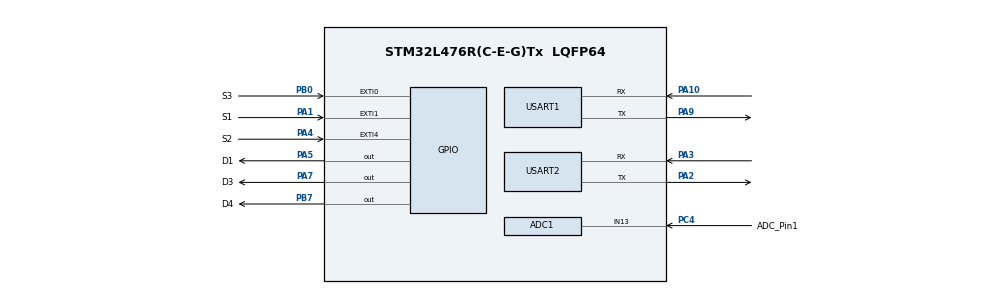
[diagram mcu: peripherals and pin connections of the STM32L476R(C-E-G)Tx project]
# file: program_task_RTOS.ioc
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ADC1.Channel-1\#ChannelRegularConversion=ADC_CHANNEL_13
ADC1.NbrOfConversionFlag=1
ADC1.OffsetNumber-1\#ChannelRegularConversion=ADC_OFFSET_NONE
ADC1.Rank-1\#ChannelRegularConversion=1
ADC1.SamplingTime-1\#ChannelRegularConversion=ADC_SAMPLETIME_2CYCLES_5
ADC1.master=1
FREERTOS.Tasks01=defaultTask,0,128,StartDefaultTask,Default,NULL,Dynamic,NULL,NULL
Mcu.Family=STM32L4
Mcu.Name=STM32L476R(C-E-G)Tx
Mcu.Package=LQFP64
NVIC.EXTI0_IRQn=true\:5\:0\:false\:false\:true\:true\:true\:true\:true
NVIC.EXTI1_IRQn=true\:5\:0\:false\:false\:true\:true\:true\:true\:true
NVIC.EXTI4_IRQn=true\:5\:0\:false\:false\:true\:true\:true\:true\:true
NVIC.PriorityGroup=NVIC_PRIORITYGROUP_4
PA1.GPIO_Label=S1
PA1.Signal=GPXTI1
PA10.Mode=Asynchronous
PA10.Signal=USART1_RX
PA2.Mode=Asynchronous
PA2.Signal=USART2_TX
PA3.Mode=Asynchronous
PA3.Signal=USART2_RX
PA4.GPIO_Label=S2
PA4.Signal=GPXTI4
PA5.GPIO_Label=D1
PA5.PinState=GPIO_PIN_SET
PA5.Signal=GPIO_Output
PA7.GPIO_Label=D3
PA7.PinState=GPIO_PIN_SET
PA7.Signal=GPIO_Output
PA9.Mode=Asynchronous
PA9.Signal=USART1_TX
PB0.GPIO_Label=S3
PB0.Signal=GPXTI0
PB7.GPIO_Label=D4
PB7.PinState=GPIO_PIN_SET
PB7.Signal=GPIO_Output
PC4.GPIO_Label=ADC_Pin1
PC4.Signal=ADCx_IN13
ProjectManager.HeapSize=0x200
ProjectManager.StackSize=0x400
ProjectManager.TargetToolchain=STM32CubeIDE
RCC.HSE_VALUE=8000000
RCC.HSI_VALUE=16000000
RCC.LSE_VALUE=32768
RCC.MSI_VALUE=4000000
RCC.VCOOutputFreq_Value=32000000
SH.ADCx_IN13.0=ADC1_IN13,IN13-Single-Ended
USART1.VirtualMode-Asynchronous=VM_ASYNC
USART2.VirtualMode-Asynchronous=VM_ASYNC
VP_FREERTOS_VS_CMSIS_V1.Mode=CMSIS_V1
board=custom

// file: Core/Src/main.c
/* USER CODE BEGIN Header */
/**
  ******************************************************************************
  * @file           : main.c
  * @brief          : Main program body
  ******************************************************************************
  * @attention
  *
  * Copyright (c) 2024 STMicroelectronics.
  * All rights reserved.
  *
  * This software is licensed under terms that can be found in the LICENSE file
  * in the root directory of this software component.
  * If no LICENSE file comes with this software, it is provided AS-IS.
  *
  ******************************************************************************
  */
/* USER CODE END Header */
#include "main.h"
#include "cmsis_os.h"

ADC_HandleTypeDef hadc1;

UART_HandleTypeDef huart1;
UART_HandleTypeDef huart2;

osThreadId defaultTaskHandle;
/* USER CODE BEGIN PV */

uint8_t flag_D1 = 0;

/* USER CODE END PV */

void SystemClock_Config(void);
static void MX_GPIO_Init(void);
static void MX_ADC1_Init(void);
static void MX_USART1_UART_Init(void);
static void MX_USART2_UART_Init(void);
void StartDefaultTask(void const * argument);

/* USER CODE BEGIN 0 */

void HAL_GPIO_EXTI_Callback(uint16_t GPIO_Pin){
	  UNUSED(GPIO_Pin);

	  if(GPIO_Pin == GPIO_PIN_1){
		flag_D1 = 1;
	  }

}

/* USER CODE END 0 */

int main(void)
{

  /* MCU Configuration--------------------------------------------------------*/

  /* Reset of all peripherals, Initializes the Flash interface and the Systick. */
  HAL_Init();

  /* Configure the system clock */
  SystemClock_Config();

  /* Initialize all configured peripherals */
  MX_GPIO_Init();
  MX_ADC1_Init();
  MX_USART1_UART_Init();
  MX_USART2_UART_Init();

  /* Create the thread(s) */
  /* definition and creation of defaultTask */
  osThreadDef(defaultTask, StartDefaultTask, osPriorityNormal, 0, 128);
  defaultTaskHandle = osThreadCreate(osThread(defaultTask), NULL);

  /* Start scheduler */
  osKernelStart();

  /* We should never get here as control is now taken by the scheduler */

  /* Infinite loop */
  while (1)
  {

    /* USER CODE BEGIN 3 */

	  if(flag_D1!=0){
		  HAL_GPIO_TogglePin(D1_GPIO_Port,D1_Pin);
		  HAL_Delay(500);
	  }

  }
  /* USER CODE END 3 */
}

void SystemClock_Config(void)
{
  RCC_OscInitTypeDef RCC_OscInitStruct = {0};
  RCC_ClkInitTypeDef RCC_ClkInitStruct = {0};

  /** Configure the main internal regulator output voltage
  */
  if (HAL_PWREx_ControlVoltageScaling(PWR_REGULATOR_VOLTAGE_SCALE1) != HAL_OK)
  {
    Error_Handler();
  }

  /** Initializes the RCC Oscillators according to the specified parameters
  * in the RCC_OscInitTypeDef structure.
  */
  RCC_OscInitStruct.OscillatorType = RCC_OSCILLATORTYPE_MSI;
  RCC_OscInitStruct.MSIState = RCC_MSI_ON;
  RCC_OscInitStruct.MSICalibrationValue = 0;
  RCC_OscInitStruct.MSIClockRange = RCC_MSIRANGE_6;
  RCC_OscInitStruct.PLL.PLLState = RCC_PLL_NONE;
  if (HAL_RCC_OscConfig(&RCC_OscInitStruct) != HAL_OK)
  {
    Error_Handler();
  }

  /** Initializes the CPU, AHB and APB buses clocks
  */
  RCC_ClkInitStruct.ClockType = RCC_CLOCKTYPE_HCLK|RCC_CLOCKTYPE_SYSCLK
                              |RCC_CLOCKTYPE_PCLK1|RCC_CLOCKTYPE_PCLK2;
  RCC_ClkInitStruct.SYSCLKSource = RCC_SYSCLKSOURCE_MSI;
  RCC_ClkInitStruct.AHBCLKDivider = RCC_SYSCLK_DIV1;
  RCC_ClkInitStruct.APB1CLKDivider = RCC_HCLK_DIV1;
  RCC_ClkInitStruct.APB2CLKDivider = RCC_HCLK_DIV1;

  if (HAL_RCC_ClockConfig(&RCC_ClkInitStruct, FLASH_LATENCY_0) != HAL_OK)
  {
    Error_Handler();
  }
}

static void MX_ADC1_Init(void)
{

  ADC_MultiModeTypeDef multimode = {0};
  ADC_ChannelConfTypeDef sConfig = {0};

  /** Common config
  */
  hadc1.Instance = ADC1;
  hadc1.Init.ClockPrescaler = ADC_CLOCK_ASYNC_DIV1;
  hadc1.Init.Resolution = ADC_RESOLUTION_12B;
  hadc1.Init.DataAlign = ADC_DATAALIGN_RIGHT;
  hadc1.Init.ScanConvMode = ADC_SCAN_DISABLE;
  hadc1.Init.EOCSelection = ADC_EOC_SINGLE_CONV;
  hadc1.Init.LowPowerAutoWait = DISABLE;
  hadc1.Init.ContinuousConvMode = DISABLE;
  hadc1.Init.NbrOfConversion = 1;
  hadc1.Init.DiscontinuousConvMode = DISABLE;
  hadc1.Init.ExternalTrigConv = ADC_SOFTWARE_START;
  hadc1.Init.ExternalTrigConvEdge = ADC_EXTERNALTRIGCONVEDGE_NONE;
  hadc1.Init.DMAContinuousRequests = DISABLE;
  hadc1.Init.Overrun = ADC_OVR_DATA_PRESERVED;
  hadc1.Init.OversamplingMode = DISABLE;
  if (HAL_ADC_Init(&hadc1) != HAL_OK)
  {
    Error_Handler();
  }

  /** Configure the ADC multi-mode
  */
  multimode.Mode = ADC_MODE_INDEPENDENT;
  if (HAL_ADCEx_MultiModeConfigChannel(&hadc1, &multimode) != HAL_OK)
  {
    Error_Handler();
  }

  /** Configure Regular Channel
  */
  sConfig.Channel = ADC_CHANNEL_13;
  sConfig.Rank = ADC_REGULAR_RANK_1;
  sConfig.SamplingTime = ADC_SAMPLETIME_2CYCLES_5;
  sConfig.SingleDiff = ADC_SINGLE_ENDED;
  sConfig.OffsetNumber = ADC_OFFSET_NONE;
  sConfig.Offset = 0;
  if (HAL_ADC_ConfigChannel(&hadc1, &sConfig) != HAL_OK)
  {
    Error_Handler();
  }

}

static void MX_USART1_UART_Init(void)
{

  huart1.Instance = USART1;
  huart1.Init.BaudRate = 115200;
  huart1.Init.WordLength = UART_WORDLENGTH_8B;
  huart1.Init.StopBits = UART_STOPBITS_1;
  huart1.Init.Parity = UART_PARITY_NONE;
  huart1.Init.Mode = UART_MODE_TX_RX;
  huart1.Init.HwFlowCtl = UART_HWCONTROL_NONE;
  huart1.Init.OverSampling = UART_OVERSAMPLING_16;
  huart1.Init.OneBitSampling = UART_ONE_BIT_SAMPLE_DISABLE;
  huart1.AdvancedInit.AdvFeatureInit = UART_ADVFEATURE_NO_INIT;
  if (HAL_UART_Init(&huart1) != HAL_OK)
  {
    Error_Handler();
  }

}

static void MX_USART2_UART_Init(void)
{

  huart2.Instance = USART2;
  huart2.Init.BaudRate = 115200;
  huart2.Init.WordLength = UART_WORDLENGTH_8B;
  huart2.Init.StopBits = UART_STOPBITS_1;
  huart2.Init.Parity = UART_PARITY_NONE;
  huart2.Init.Mode = UART_MODE_TX_RX;
  huart2.Init.HwFlowCtl = UART_HWCONTROL_NONE;
  huart2.Init.OverSampling = UART_OVERSAMPLING_16;
  huart2.Init.OneBitSampling = UART_ONE_BIT_SAMPLE_DISABLE;
  huart2.AdvancedInit.AdvFeatureInit = UART_ADVFEATURE_NO_INIT;
  if (HAL_UART_Init(&huart2) != HAL_OK)
  {
    Error_Handler();
  }

}

static void MX_GPIO_Init(void)
{
  GPIO_InitTypeDef GPIO_InitStruct = {0};

  /* GPIO Ports Clock Enable */
  __HAL_RCC_GPIOA_CLK_ENABLE();
  __HAL_RCC_GPIOC_CLK_ENABLE();
  __HAL_RCC_GPIOB_CLK_ENABLE();

  /*Configure GPIO pin Output Level */
  HAL_GPIO_WritePin(GPIOA, D1_Pin|D3_Pin, GPIO_PIN_SET);

  /*Configure GPIO pin Output Level */
  HAL_GPIO_WritePin(D4_GPIO_Port, D4_Pin, GPIO_PIN_SET);

  /*Configure GPIO pins : S1_Pin S2_Pin */
  GPIO_InitStruct.Pin = S1_Pin|S2_Pin;
  GPIO_InitStruct.Mode = GPIO_MODE_IT_RISING;
  GPIO_InitStruct.Pull = GPIO_NOPULL;
  HAL_GPIO_Init(GPIOA, &GPIO_InitStruct);

  /*Configure GPIO pins : D1_Pin D3_Pin */
  GPIO_InitStruct.Pin = D1_Pin|D3_Pin;
  GPIO_InitStruct.Mode = GPIO_MODE_OUTPUT_PP;
  GPIO_InitStruct.Pull = GPIO_NOPULL;
  GPIO_InitStruct.Speed = GPIO_SPEED_FREQ_LOW;
  HAL_GPIO_Init(GPIOA, &GPIO_InitStruct);

  /*Configure GPIO pin : S3_Pin */
  GPIO_InitStruct.Pin = S3_Pin;
  GPIO_InitStruct.Mode = GPIO_MODE_IT_RISING;
  GPIO_InitStruct.Pull = GPIO_NOPULL;
  HAL_GPIO_Init(S3_GPIO_Port, &GPIO_InitStruct);

  /*Configure GPIO pin : D4_Pin */
  GPIO_InitStruct.Pin = D4_Pin;
  GPIO_InitStruct.Mode = GPIO_MODE_OUTPUT_PP;
  GPIO_InitStruct.Pull = GPIO_NOPULL;
  GPIO_InitStruct.Speed = GPIO_SPEED_FREQ_LOW;
  HAL_GPIO_Init(D4_GPIO_Port, &GPIO_InitStruct);

  /* EXTI interrupt init*/
  HAL_NVIC_SetPriority(EXTI0_IRQn, 5, 0);
  HAL_NVIC_EnableIRQ(EXTI0_IRQn);

  HAL_NVIC_SetPriority(EXTI1_IRQn, 5, 0);
  HAL_NVIC_EnableIRQ(EXTI1_IRQn);

  HAL_NVIC_SetPriority(EXTI4_IRQn, 5, 0);
  HAL_NVIC_EnableIRQ(EXTI4_IRQn);

}

void StartDefaultTask(void const * argument)
{
  for(;;)
  {
    osDelay(1);
  }
}

void Error_Handler(void)
{
  __disable_irq();
  while (1)
  {
  }
}
